# SD16_A4_1 register map
Vendor: Texas Instruments
Peripheral module from a debugger description file (folder msp430).
Registers are 16-bit, read-write, reset 0x0 unless marked. A register's access mark holds for its fields unless they carry their own. Offsets are as the file gives them; lines under a group give offsets from that group; [hi:lo] are bit positions; {n}, {i} and the like mark numbered series; 'fields as' and 'values as' point back to an identical list; <NAME> marks a mode.

## SD16_A4
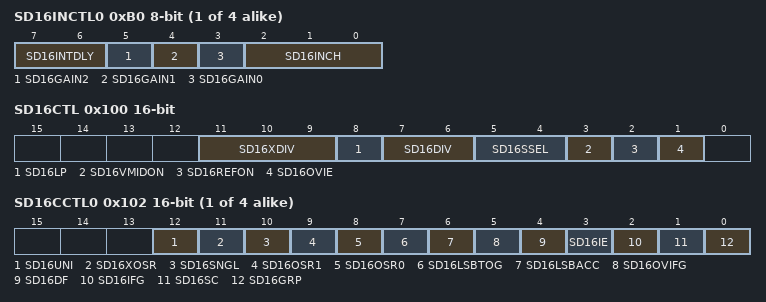
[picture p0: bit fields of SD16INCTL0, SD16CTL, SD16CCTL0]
{0xB0+i} SD16INCTL{i} 8-bit (i=0..3) — SD16 Input Control Register Channel {i}
  [7:6] SD16INTDLY — SD16 Interrupt Delay after 1.Conversion 0
    0=SD16 Interrupt Delay: Int. after 4.Conversion; 1=SD16 Interrupt Delay: Int. after 3.Conversion; 2=SD16 Interrupt Delay: Int. after 2.Conversion; 3=SD16 Interrupt Delay: Int. after 1.Conversion
  [5] SD16GAIN2 — SD16 Input Pre-Amplifier Gain Select 2
  [4] SD16GAIN1 — SD16 Input Pre-Amplifier Gain Select 1
  [3] SD16GAIN0 — SD16 Input Pre-Amplifier Gain Select 0
  [2:0] SD16INCH — SD16 Input Channel select 0
    {v}=SD16 Input Channel select input (v=0..4); 5=SD16 Input Channel select Vcc divider; 6=SD16 Input Channel select Temp; 7=SD16 Input Channel select Offset
{0xB8+i} SD16PRE{i} 8-bit access not given reset not defined (i=0..3) — SD16 Preload Register Channel {i}
0x100 SD16CTL — Sigma Delta ADC 16 Control Register
  [11:9] SD16XDIV — SD16 2.Clock Divider Select 0
    0=SD16 2.Clock Divider Select /1; 1=SD16 2.Clock Divider Select /3; 2=SD16 2.Clock Divider Select /16; 3=SD16 2.Clock Divider Select /48
  [8] SD16LP — SD16 Low Power Mode Enable
  [7:6] SD16DIV — SD16 Clock Divider Select 0
    0=SD16 Clock Divider Select /1; 1=SD16 Clock Divider Select /2; 2=SD16 Clock Divider Select /4; 3=SD16 Clock Divider Select /8
  [5:4] SD16SSEL — SD16 Clock Source Select 0
    0=SD16 Clock Source Select MCLK; 1=SD16 Clock Source Select SMCLK; 2=SD16 Clock Source Select ACLK; 3=SD16 Clock Source Select TACLK
  [3] SD16VMIDON — SD16 Switch Vmid Buffer on
  [2] SD16REFON — SD16 Switch internal Reference on
  [1] SD16OVIE — SD16 Overflow Interupt Enable
{0x102+2i} SD16CCTL{i} (i=0..3) — SD16 Channel {i} Control Register
  [12] SD16UNI — SD16 Channel x Bipolar(0) / Unipolar(1) Mode
  [11] SD16XOSR — SD16 Channel x Extended OverSampling Ratio
  [10] SD16SNGL — SD16 Channel x Single Conversion On/Off
  [9] SD16OSR1 — SD16 Channel x OverSampling Ratio 1
  [8] SD16OSR0 — SD16 Channel x OverSampling Ratio 0
  [7] SD16LSBTOG — SD16 Channel x Toggle LSB Output of ADC
  [6] SD16LSBACC — SD16 Channel x Access LSB of ADC
  [5] SD16OVIFG — SD16 Channel x Overflow Interrupt Flag
  [4] SD16DF — SD16 Channel x Data Format: 0:Unipolar/1:Bipolar
  [3] SD16IE — SD16 Channel x Interrupt Enable
  [2] SD16IFG — SD16 Channel x Interrupt Flag
  [1] SD16SC — SD16 Start Conversion
  [0] SD16GRP — SD16 Grouping of Channels: 0:Off/1:On
0x110 SD16IV access not given reset not defined — SD16 Interrupt Vector Register
{0x112+2i} SD16MEM{i} access not given reset not defined (i=0..3) — SD16 Channel {i} Conversion Memory
